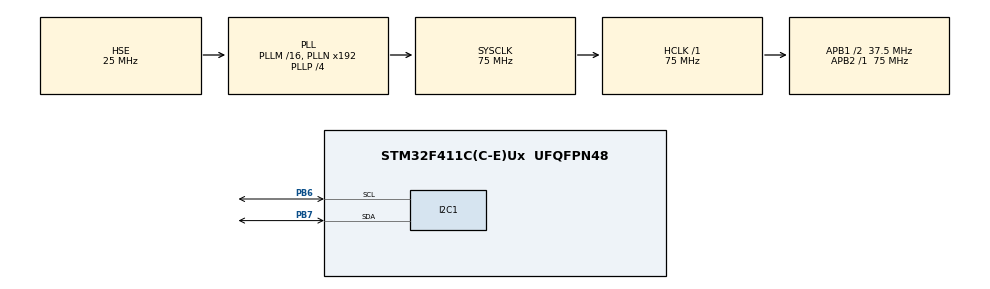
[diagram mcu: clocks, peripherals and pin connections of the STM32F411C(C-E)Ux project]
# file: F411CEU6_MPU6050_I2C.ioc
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Mcu.Family=STM32F4
Mcu.Name=STM32F411C(C-E)Ux
Mcu.Package=UFQFPN48
NVIC.PriorityGroup=NVIC_PRIORITYGROUP_4
PA13.Mode=Serial_Wire
PA13.Signal=SYS_JTMS-SWDIO
PA14.Mode=Serial_Wire
PA14.Signal=SYS_JTCK-SWCLK
PB6.Mode=I2C
PB6.Signal=I2C1_SCL
PB7.Mode=I2C
PB7.Signal=I2C1_SDA
PH0\ -\ OSC_IN.Mode=HSE-External-Oscillator
PH0\ -\ OSC_IN.Signal=RCC_OSC_IN
PH1\ -\ OSC_OUT.Mode=HSE-External-Oscillator
PH1\ -\ OSC_OUT.Signal=RCC_OSC_OUT
ProjectManager.HeapSize=0x200
ProjectManager.StackSize=0x400
ProjectManager.TargetToolchain=STM32CubeIDE
RCC.48MHZClocksFreq_Value=75000000
RCC.AHBFreq_Value=75000000
RCC.APB1CLKDivider=RCC_HCLK_DIV2
RCC.APB1Freq_Value=37500000
RCC.APB1TimFreq_Value=75000000
RCC.APB2Freq_Value=75000000
RCC.APB2TimFreq_Value=75000000
RCC.CortexFreq_Value=75000000
RCC.HCLKFreq_Value=75000000
RCC.HSE_VALUE=25000000
RCC.HSI_VALUE=16000000
RCC.LSE_VALUE=32768
RCC.PLLP=RCC_PLLP_DIV4
RCC.PLLSourceVirtual=RCC_PLLSOURCE_HSE
RCC.SYSCLKFreq_VALUE=75000000
RCC.SYSCLKSource=RCC_SYSCLKSOURCE_PLLCLK
RCC.VCOOutputFreq_Value=300000000
board=custom

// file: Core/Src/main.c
/* USER CODE BEGIN Header */
/**
  ******************************************************************************
  * @file           : main.c
  * @brief          : Main program body
  ******************************************************************************
  * @attention
  *
  * Copyright (c) 2023 STMicroelectronics.
  * All rights reserved.
  *
  * This software is licensed under terms that can be found in the LICENSE file
  * in the root directory of this software component.
  * If no LICENSE file comes with this software, it is provided AS-IS.
  *
  ******************************************************************************
  */
/* USER CODE END Header */
#include "main.h"

I2C_HandleTypeDef hi2c1;

void SystemClock_Config(void);
static void MX_GPIO_Init(void);
static void MX_I2C1_Init(void);

/* USER CODE BEGIN 0 */
#define MPU6050_ADDRESS 0xD0

#define WHO_AM_I_REG     0x75
#define PWR_MGMT_1_REG   0x6B
#define SMPLRT_DIV_REG   0x19
#define GYRO_CONFIG_REG  0x1B
#define ACCEL_CONFIG_REG 0x1C
#define ACCEL_XOUT_H_REG 0x3B
#define GYRO_XOUT_H_REG  0x43

void MPU6050_Init() {
	uint8_t check, data;
	HAL_I2C_Mem_Read(&hi2c1, MPU6050_ADDRESS, WHO_AM_I_REG, 1, &check, 1, 1000);
	if (check == 104) { // 0x68
		data = 0;
		HAL_I2C_Mem_Write(&hi2c1, MPU6050_ADDRESS, PWR_MGMT_1_REG, 1, &data, 1, 1000);

		data = 0x07;
		HAL_I2C_Mem_Write(&hi2c1, MPU6050_ADDRESS, SMPLRT_DIV_REG, 1, &data, 1, 1000);

		data = 0x00;
		HAL_I2C_Mem_Write(&hi2c1, MPU6050_ADDRESS, GYRO_CONFIG_REG, 1, &data, 1, 1000);

		data = 0x00;
		HAL_I2C_Mem_Write(&hi2c1, MPU6050_ADDRESS, ACCEL_CONFIG_REG, 1, &data, 1, 1000);
	}
}

int16_t Accel_X_Raw, Accel_Y_Raw, Accel_Z_Raw, Gyro_X_Raw, Gyro_Y_Raw, Gyro_Z_Raw;
float Ax, Ay, Az, Gx, Gy, Gz;

void MPU6050_Read_Accel() {
	uint8_t rec_data[6];

	HAL_I2C_Mem_Read(&hi2c1, MPU6050_ADDRESS, ACCEL_XOUT_H_REG, 1, &rec_data, 6, 1000);
	Accel_X_Raw = (int16_t)(rec_data[0] << 8 | rec_data[1]);
	Accel_Y_Raw = (int16_t)(rec_data[2] << 8 | rec_data[3]);
	Accel_Z_Raw = (int16_t)(rec_data[4] << 8 | rec_data[5]);

	Ax = Accel_X_Raw / 16384.0;
	Ay = Accel_Y_Raw / 16384.0;
	Az = Accel_Z_Raw / 16384.0;
}

void MPU6050_Read_Gyro() {
	uint8_t rec_data[6];

	HAL_I2C_Mem_Read(&hi2c1, MPU6050_ADDRESS, GYRO_XOUT_H_REG, 1, &rec_data, 6, 1000);
	Gyro_X_Raw = (int16_t)(rec_data[0] << 8 | rec_data[1]);
	Gyro_Y_Raw = (int16_t)(rec_data[2] << 8 | rec_data[3]);
	Gyro_Z_Raw = (int16_t)(rec_data[4] << 8 | rec_data[5]);

	Gx = Gyro_X_Raw / 131.0;
	Gy = Gyro_Y_Raw / 131.0;
	Gz = Gyro_Z_Raw / 131.0;
}
/* USER CODE END 0 */

int main(void)
{

  /* MCU Configuration--------------------------------------------------------*/

  /* Reset of all peripherals, Initializes the Flash interface and the Systick. */
  HAL_Init();

  /* Configure the system clock */
  SystemClock_Config();

  /* Initialize all configured peripherals */
  MX_GPIO_Init();
  MX_I2C1_Init();
  /* USER CODE BEGIN 2 */
  MPU6050_Init();
  /* USER CODE END 2 */

  /* Infinite loop */
  while (1)
  {

    /* USER CODE BEGIN 3 */
	  MPU6050_Read_Accel();
	  MPU6050_Read_Gyro();

	  HAL_Delay(250);
  }
  /* USER CODE END 3 */
}

void SystemClock_Config(void)
{
  RCC_OscInitTypeDef RCC_OscInitStruct = {0};
  RCC_ClkInitTypeDef RCC_ClkInitStruct = {0};

  /** Configure the main internal regulator output voltage
  */
  __HAL_RCC_PWR_CLK_ENABLE();
  __HAL_PWR_VOLTAGESCALING_CONFIG(PWR_REGULATOR_VOLTAGE_SCALE1);

  /** Initializes the RCC Oscillators according to the specified parameters
  * in the RCC_OscInitTypeDef structure.
  */
  RCC_OscInitStruct.OscillatorType = RCC_OSCILLATORTYPE_HSE;
  RCC_OscInitStruct.HSEState = RCC_HSE_ON;
  RCC_OscInitStruct.PLL.PLLState = RCC_PLL_ON;
  RCC_OscInitStruct.PLL.PLLSource = RCC_PLLSOURCE_HSE;
  RCC_OscInitStruct.PLL.PLLM = 16;
  RCC_OscInitStruct.PLL.PLLN = 192;
  RCC_OscInitStruct.PLL.PLLP = RCC_PLLP_DIV4;
  RCC_OscInitStruct.PLL.PLLQ = 4;
  if (HAL_RCC_OscConfig(&RCC_OscInitStruct) != HAL_OK)
  {
    Error_Handler();
  }

  /** Initializes the CPU, AHB and APB buses clocks
  */
  RCC_ClkInitStruct.ClockType = RCC_CLOCKTYPE_HCLK|RCC_CLOCKTYPE_SYSCLK
                              |RCC_CLOCKTYPE_PCLK1|RCC_CLOCKTYPE_PCLK2;
  RCC_ClkInitStruct.SYSCLKSource = RCC_SYSCLKSOURCE_PLLCLK;
  RCC_ClkInitStruct.AHBCLKDivider = RCC_SYSCLK_DIV1;
  RCC_ClkInitStruct.APB1CLKDivider = RCC_HCLK_DIV2;
  RCC_ClkInitStruct.APB2CLKDivider = RCC_HCLK_DIV1;

  if (HAL_RCC_ClockConfig(&RCC_ClkInitStruct, FLASH_LATENCY_2) != HAL_OK)
  {
    Error_Handler();
  }
}

static void MX_I2C1_Init(void)
{

  hi2c1.Instance = I2C1;
  hi2c1.Init.ClockSpeed = 100000;
  hi2c1.Init.DutyCycle = I2C_DUTYCYCLE_2;
  hi2c1.Init.OwnAddress1 = 0;
  hi2c1.Init.AddressingMode = I2C_ADDRESSINGMODE_7BIT;
  hi2c1.Init.DualAddressMode = I2C_DUALADDRESS_DISABLE;
  hi2c1.Init.OwnAddress2 = 0;
  hi2c1.Init.GeneralCallMode = I2C_GENERALCALL_DISABLE;
  hi2c1.Init.NoStretchMode = I2C_NOSTRETCH_DISABLE;
  if (HAL_I2C_Init(&hi2c1) != HAL_OK)
  {
    Error_Handler();
  }

}

static void MX_GPIO_Init(void)
{

  /* GPIO Ports Clock Enable */
  __HAL_RCC_GPIOH_CLK_ENABLE();
  __HAL_RCC_GPIOA_CLK_ENABLE();
  __HAL_RCC_GPIOB_CLK_ENABLE();

}

void Error_Handler(void)
{
  __disable_irq();
  while (1)
  {
  }
}
